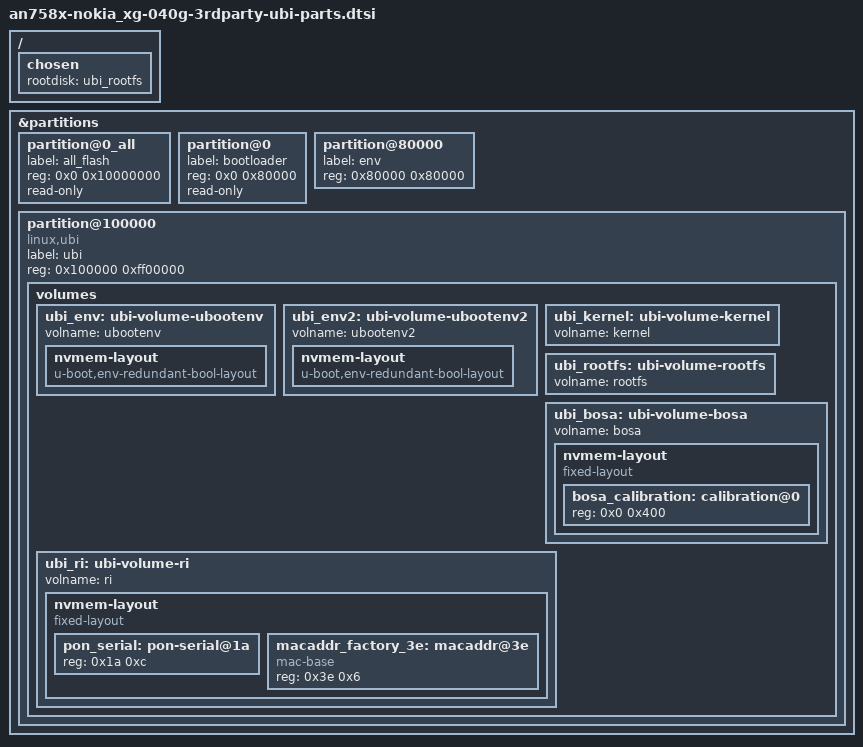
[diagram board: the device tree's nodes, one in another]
// SPDX-License-Identifier: GPL-2.0-only OR MIT

/ {
	chosen {
		rootdisk = <&ubi_rootfs>;
	};
};

&partitions {
	partition@0_all {
		label = "all_flash";
		reg = <0x0 0x10000000>;
		read-only;
	};

	partition@0 {
		label = "bootloader";
		reg = <0x0 0x80000>;
		read-only;
	};

	partition@80000 {
		label = "env";
		reg = <0x80000 0x80000>;
	};

	partition@100000 {
		label = "ubi";
		reg = <0x100000 0xff00000>;
		compatible = "linux,ubi";

		volumes {
			ubi_env: ubi-volume-ubootenv {
				volname = "ubootenv";
			};

			ubi_env2: ubi-volume-ubootenv2 {
				volname = "ubootenv2";
			};

			ubi_kernel: ubi-volume-kernel {
				volname = "kernel";
			};

			ubi_rootfs: ubi-volume-rootfs {
				volname = "rootfs";
			};

			ubi_bosa: ubi-volume-bosa {
				volname = "bosa";
				nvmem-layout {
					compatible = "fixed-layout";
					#address-cells = <1>;
					#size-cells = <1>;
					bosa_calibration: calibration@0 {
						reg = <0x0 0x400>;
					};
				};
			};

			ubi_ri: ubi-volume-ri {
				volname = "ri";
				nvmem-layout {
					compatible = "fixed-layout";
					#address-cells = <1>;
					#size-cells = <1>;
					pon_serial: pon-serial@1a {
						reg = <0x1a 0xc>;
					};
					macaddr_factory_3e: macaddr@3e {
						compatible = "mac-base";
						reg = <0x3e 0x6>;
						#nvmem-cell-cells = <1>;
					};
				};
			};
		};
	};
};

&ubi_env {
	nvmem-layout {
		compatible = "u-boot,env-redundant-bool-layout";
	};
};

&ubi_env2 {
	nvmem-layout {
		compatible = "u-boot,env-redundant-bool-layout";
	};
};
